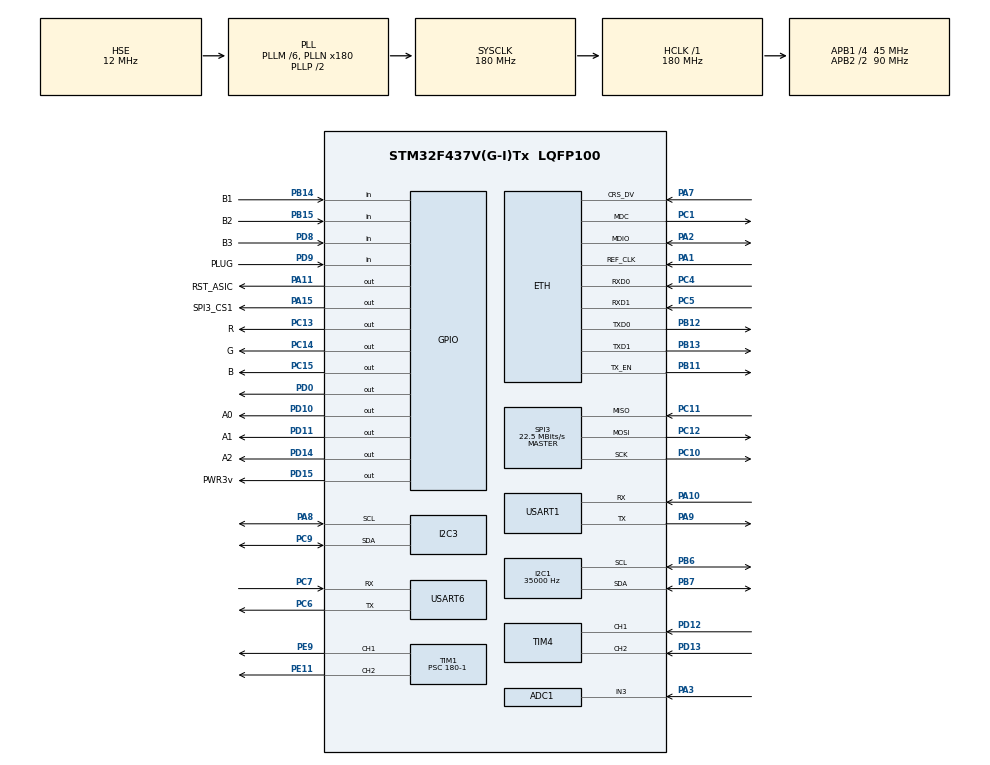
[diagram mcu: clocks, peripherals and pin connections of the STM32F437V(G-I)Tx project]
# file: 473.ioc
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ADC1.Channel-0\#ChannelRegularConversion=ADC_CHANNEL_3
ADC1.NbrOfConversionFlag=1
ADC1.Rank-0\#ChannelRegularConversion=1
ADC1.SamplingTime-0\#ChannelRegularConversion=ADC_SAMPLETIME_3CYCLES
ADC1.master=1
ETH.MediaInterface=ETH_MEDIA_INTERFACE_RMII
FREERTOS.Tasks01=testTask,0,256,TestTask,Default,NULL,Dynamic,NULL,NULL;lcdTask,0,512,LCDTask,Default,NULL,Dynamic,NULL,NULL;I2C_Task,0,256,i2c_Task,Default,NULL,Dynamic,NULL,NULL;buttonTask,0,128,ButtonTask,Default,NULL,Dynamic,NULL,NULL
FREERTOS.configUSE_NEWLIB_REENTRANT=1
I2C1.ClockSpeed=35000
I2C1.I2C_Mode=I2C_Fast
I2C3.I2C_Mode=I2C_Fast
Mcu.Family=STM32F4
Mcu.Name=STM32F437V(G-I)Tx
Mcu.Package=LQFP100
NVIC.PriorityGroup=NVIC_PRIORITYGROUP_4
NVIC.TIM7_IRQn=true\:15\:0\:false\:false\:true\:false\:false\:true\:true
NVIC.TimeBase=TIM7_IRQn
NVIC.TimeBaseIP=TIM7
NVIC.USART1_IRQn=true\:5\:0\:false\:false\:true\:true\:true\:true\:true
NVIC.USART6_IRQn=true\:5\:0\:false\:false\:true\:true\:true\:true\:true
PA1.Mode=RMII
PA1.Signal=ETH_REF_CLK
PA10.Mode=Asynchronous
PA10.Signal=USART1_RX
PA11.GPIO_Label=RST_ASIC
PA11.Signal=GPIO_Output
PA13.Mode=Serial_Wire
PA13.Signal=SYS_JTMS-SWDIO
PA14.Mode=Serial_Wire
PA14.Signal=SYS_JTCK-SWCLK
PA15.GPIO_Label=SPI3_CS1
PA15.Signal=GPIO_Output
PA2.Mode=RMII
PA2.Signal=ETH_MDIO
PA3.Signal=ADCx_IN3
PA7.Mode=RMII
PA7.Signal=ETH_CRS_DV
PA8.Mode=I2C
PA8.Signal=I2C3_SCL
PA9.Mode=Asynchronous
PA9.Signal=USART1_TX
PB11.Mode=RMII
PB11.Signal=ETH_TX_EN
PB12.Mode=RMII
PB12.Signal=ETH_TXD0
PB13.Mode=RMII
PB13.Signal=ETH_TXD1
PB14.GPIO_Label=B1
PB14.GPIO_PuPd=GPIO_PULLUP
PB14.Signal=GPIO_Input
PB15.GPIO_Label=B2
PB15.GPIO_PuPd=GPIO_PULLUP
PB15.Signal=GPIO_Input
PB3.Signal=SYS_JTDO-SWO
PB5.Signal=S_TIM3_CH2
PB6.Mode=I2C
PB6.Signal=I2C1_SCL
PB7.Mode=I2C
PB7.Signal=I2C1_SDA
PC1.Mode=RMII
PC1.Signal=ETH_MDC
PC10.Mode=Full_Duplex_Master
PC10.Signal=SPI3_SCK
PC11.Mode=Full_Duplex_Master
PC11.Signal=SPI3_MISO
PC12.Mode=Full_Duplex_Master
PC12.Signal=SPI3_MOSI
PC13.GPIO_Label=R
PC13.Signal=GPIO_Output
PC14/OSC32_IN.GPIO_Label=G
PC14/OSC32_IN.Signal=GPIO_Output
PC15/OSC32_OUT.GPIO_Label=B
PC15/OSC32_OUT.Signal=GPIO_Output
PC4.Mode=RMII
PC4.Signal=ETH_RXD0
PC5.Mode=RMII
PC5.Signal=ETH_RXD1
PC6.Mode=Asynchronous
PC6.Signal=USART6_TX
PC7.Mode=Asynchronous
PC7.Signal=USART6_RX
PC9.Mode=I2C
PC9.Signal=I2C3_SDA
PD0.Signal=GPIO_Output
PD10.GPIO_Label=A0
PD10.Signal=GPIO_Output
PD11.GPIO_Label=A1
PD11.Signal=GPIO_Output
PD12.GPIO_PuPd=GPIO_PULLUP
PD12.Signal=S_TIM4_CH1
PD13.GPIO_PuPd=GPIO_PULLUP
PD13.Signal=S_TIM4_CH2
PD14.GPIO_Label=A2
PD14.Signal=GPIO_Output
PD15.GPIO_Label=PWR3v
PD15.Signal=GPIO_Output
PD4.Signal=USART2_RTS
PD5.Signal=USART2_TX
PD6.Signal=USART2_RX
PD8.GPIO_Label=B3
PD8.GPIO_PuPd=GPIO_PULLUP
PD8.Signal=GPIO_Input
PD9.GPIO_Label=PLUG
PD9.Signal=GPIO_Input
PE11.Signal=S_TIM1_CH2
PE9.Signal=S_TIM1_CH1
PH0/OSC_IN.Mode=HSE-External-Oscillator
PH0/OSC_IN.Signal=RCC_OSC_IN
PH1/OSC_OUT.Mode=HSE-External-Oscillator
PH1/OSC_OUT.Signal=RCC_OSC_OUT
ProjectManager.HeapSize=0x2000
ProjectManager.StackSize=0x4000
ProjectManager.TargetToolchain=EWARM V8.32
RCC.48MHZClocksFreq_Value=90000000
RCC.AHBFreq_Value=180000000
RCC.APB1CLKDivider=RCC_HCLK_DIV4
RCC.APB1Freq_Value=45000000
RCC.APB1TimFreq_Value=90000000
RCC.APB2CLKDivider=RCC_HCLK_DIV2
RCC.APB2Freq_Value=90000000
RCC.APB2TimFreq_Value=180000000
RCC.CortexFreq_Value=180000000
RCC.HCLKFreq_Value=180000000
RCC.HSE_VALUE=12000000
RCC.HSI_VALUE=16000000
RCC.LSE_VALUE=32768
RCC.PLLM=6
RCC.PLLN=180
RCC.PLLSourceVirtual=RCC_PLLSOURCE_HSE
RCC.SYSCLKFreq_VALUE=180000000
RCC.SYSCLKSource=RCC_SYSCLKSOURCE_PLLCLK
RCC.VCOOutputFreq_Value=360000000
SH.ADCx_IN3.0=ADC1_IN3,IN3
SH.S_TIM1_CH1.0=TIM1_CH1,PWM Generation1 CH1
SH.S_TIM1_CH2.0=TIM1_CH2,PWM Generation2 CH2
SH.S_TIM3_CH2.0=TIM3_CH2
SH.S_TIM4_CH1.0=TIM4_CH1,Encoder_Interface
SH.S_TIM4_CH2.0=TIM4_CH2,Encoder_Interface
SPI3.CalculateBaudRate=22.5 MBits/s
SPI3.Direction=SPI_DIRECTION_2LINES
SPI3.Mode=SPI_MODE_MASTER
SPI3.VirtualType=VM_MASTER
TIM1.Channel-PWM\ Generation1\ CH1=TIM_CHANNEL_1
TIM1.Channel-PWM\ Generation2\ CH2=TIM_CHANNEL_2
TIM1.Period=40
TIM1.Prescaler=180-1
USART1.VirtualMode=VM_ASYNC
USART6.VirtualMode=VM_ASYNC
VP_FREERTOS_VS_CMSIS_V1.Mode=CMSIS_V1
VP_SYS_VS_tim7.Mode=TIM7
VP_TIM1_VS_ClockSourceINT.Mode=Internal
board=custom

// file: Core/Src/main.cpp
/* USER CODE BEGIN Header */
/**
  ******************************************************************************
  * @file           : main.c
  * @brief          : Main program body
  ******************************************************************************
  * @attention
  *
  * <h2><center>&copy; Copyright (c) 2021 STMicroelectronics.
  * All rights reserved.</center></h2>
  *
  * This software component is licensed by ST under BSD 3-Clause license,
  * the "License"; You may not use this file except in compliance with the
  * License. You may obtain a copy of the License at:
  *                        opensource.org/licenses/BSD-3-Clause
  *
  ******************************************************************************
  */
/* USER CODE END Header */
#include "main.h"
#include "cmsis_os.h"
#include "adc.h"
#include "eth.h"
#include "i2c.h"
#include "spi.h"
#include "tim.h"
#include "usart.h"
#include "gpio.h"

/* USER CODE BEGIN PV */
extern osSemaphoreId endASICHandle;
//переменные для таймеров
uint32_t uartTIM = 0;
uint8_t status_uartTIM = 0;
uint32_t counterRefresh = 0;

/* USER CODE END PV */

void SystemClock_Config(void);
void MX_FREERTOS_Init(void);

int main(void)
{

  /* MCU Configuration--------------------------------------------------------*/

  /* Reset of all peripherals, Initializes the Flash interface and the Systick. */
  HAL_Init();

  /* Configure the system clock */
  SystemClock_Config();

  /* Initialize all configured peripherals */
  MX_GPIO_Init();
  MX_ADC1_Init();
  MX_ETH_Init();
  MX_I2C1_Init();
  MX_I2C3_Init();
  MX_SPI3_Init();
  MX_TIM1_Init();
  MX_TIM4_Init();
  MX_USART1_UART_Init();
  MX_USART6_UART_Init();

  /* Call init function for freertos objects (in freertos.c) */
  MX_FREERTOS_Init();
  /* Start scheduler */
  osKernelStart();

  /* We should never get here as control is now taken by the scheduler */
  /* Infinite loop */
  while (1)
  {

  }
}

void SystemClock_Config(void)
{
  RCC_OscInitTypeDef RCC_OscInitStruct = {0};
  RCC_ClkInitTypeDef RCC_ClkInitStruct = {0};

  /** Configure the main internal regulator output voltage
  */
  __HAL_RCC_PWR_CLK_ENABLE();
  __HAL_PWR_VOLTAGESCALING_CONFIG(PWR_REGULATOR_VOLTAGE_SCALE1);
  /** Initializes the RCC Oscillators according to the specified parameters
  * in the RCC_OscInitTypeDef structure.
  */
  RCC_OscInitStruct.OscillatorType = RCC_OSCILLATORTYPE_HSE;
  RCC_OscInitStruct.HSEState = RCC_HSE_ON;
  RCC_OscInitStruct.PLL.PLLState = RCC_PLL_ON;
  RCC_OscInitStruct.PLL.PLLSource = RCC_PLLSOURCE_HSE;
  RCC_OscInitStruct.PLL.PLLM = 6;
  RCC_OscInitStruct.PLL.PLLN = 180;
  RCC_OscInitStruct.PLL.PLLP = RCC_PLLP_DIV2;
  RCC_OscInitStruct.PLL.PLLQ = 4;
  if (HAL_RCC_OscConfig(&RCC_OscInitStruct) != HAL_OK)
  {
    Error_Handler();
  }
  /** Activate the Over-Drive mode
  */
  if (HAL_PWREx_EnableOverDrive() != HAL_OK)
  {
    Error_Handler();
  }
  /** Initializes the CPU, AHB and APB buses clocks
  */
  RCC_ClkInitStruct.ClockType = RCC_CLOCKTYPE_HCLK|RCC_CLOCKTYPE_SYSCLK
                              |RCC_CLOCKTYPE_PCLK1|RCC_CLOCKTYPE_PCLK2;
  RCC_ClkInitStruct.SYSCLKSource = RCC_SYSCLKSOURCE_PLLCLK;
  RCC_ClkInitStruct.AHBCLKDivider = RCC_SYSCLK_DIV1;
  RCC_ClkInitStruct.APB1CLKDivider = RCC_HCLK_DIV4;
  RCC_ClkInitStruct.APB2CLKDivider = RCC_HCLK_DIV2;

  if (HAL_RCC_ClockConfig(&RCC_ClkInitStruct, FLASH_LATENCY_5) != HAL_OK)
  {
    Error_Handler();
  }
}

void HAL_TIM_PeriodElapsedCallback(TIM_HandleTypeDef *htim)
{
  /* USER CODE BEGIN Callback 0 */
	  if (htim->Instance == TIM7) {
	    if (status_uartTIM) {
	    	uartTIM++;
		}
	    counterRefresh ++;

	  }

  /* USER CODE END Callback 0 */
  if (htim->Instance == TIM7) {
    HAL_IncTick();
  }
}

void Error_Handler(void)
{
  __disable_irq();
  while (1)
  {
  }
}
